# ATSAML11E15A register map
Vendor: Microchip Technology; Series: SAML11; File version: 0
CPU: CM23 r0p0, selectable endian, MPU, no FPU, 2 interrupt priority bits
Registers are 32-bit, read-write, reset 0x0 unless marked. A register's access mark holds for its fields unless they carry their own. Offsets are from the block's base; [hi:lo] are bit positions; 'fields as' and 'values as' point back to an identical list.

## OPAMP — Operational Amplifier
Base 0x42003000; register names take the prefix OPAMP_
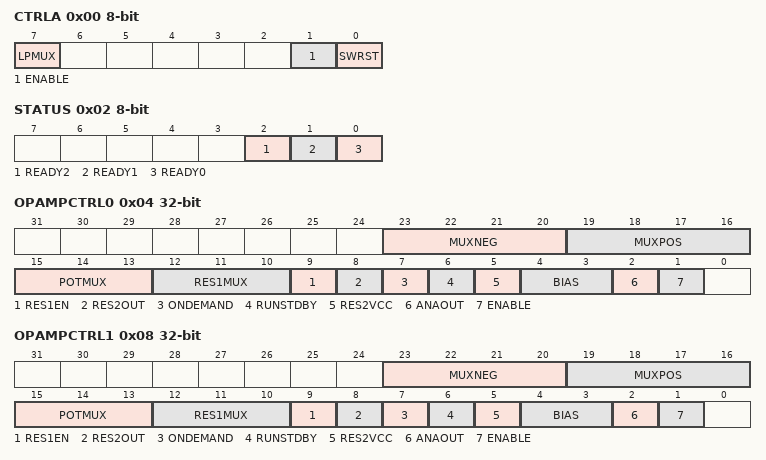
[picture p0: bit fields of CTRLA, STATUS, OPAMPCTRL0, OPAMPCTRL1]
0x00 CTRLA 8-bit — Control A
  [7] LPMUX — Low-Power Mux
  [1] ENABLE
  [0] SWRST — Software Reset
0x02 STATUS 8-bit ro
  [2] READY2 — OPAMP 2 Ready
  [1] READY1 — OPAMP 1 Ready
  [0] READY0 — OPAMP 0 Ready
0x04 OPAMPCTRL0 — OPAMP0 Control
  [23:20] MUXNEG — Negative Input Mux Selection
    0=OA0NEG (Negative I/O pin); 1=OA0TAP (Resistor ladder 0 taps); 2=REFERENCE_DAC (REFERENCE or DAC output); 3=OA0OUT (OPAMP0 output)
  [19:16] MUXPOS — Positive Input Mux Selection
    0=OA0POS (Positive I/O pin); 1=OA0TAP (Resistor ladder 0 taps); 2=REFERENCE_DAC (REFERENCE or DAC output); 3=GND (Ground)
  [15:13] POTMUX — Potentiometer Selection
    0=14R_2R (Gain = 0.14); 1=12R_4R (Gain = 0.33); 2=8R_8R (Gain = 1); 3=6R_10R (Gain = 1.67); 4=4R_12R (Gain = 3); 5=3R_13R (Gain = 4.33); 6=2R_14R (Gain = 7); 7=R_15R (Gain = 15)
  [12:10] RES1MUX — Resistor 1 Mux
    0=OAxPOS (Positive inout of OPAMPx); 1=OAxNEG (Negative input of OPAMPx); 2=DAC (DAC output); 3=GND (Ground); 4=RG_CONN
  [9] RES1EN — Resistor 1 Enable
  [8] RES2OUT — Resistor ladder To Output
  [7] ONDEMAND — On Demand Control
  [6] RUNSTDBY — Run in Standby
  [5] RES2VCC — Resistor ladder To VCC
  [4:3] BIAS — Bias Selection
  [2] ANAOUT — Analog Output
  [1] ENABLE — Operational Amplifier Enable
0x08 OPAMPCTRL1 — OPAMP1 Control
  [23:20] MUXNEG — Negative Input Mux Selection
    values as OPAMPCTRL0.MUXNEG
  [19:16] MUXPOS — Positive Input Mux Selection
    0=OA1POS (Positive I/O pin); 1=OA1TAP (Resistor ladder 1 taps); 2=REFERENCE_DAC (REFERENCE or DAC output); 3=GND (Ground); 4=OA0OUT (OPAMP0 output)
  [15:13] POTMUX — Potentiometer Selection
    values as OPAMPCTRL0.POTMUX
  [12:10] RES1MUX — Resistor 1 Mux
    0=OAxPOS (Positive inout of OPAMPx); 1=OAxNEG (Negative input of OPAMPx); 2=OA0OUT (OPAMP0 output); 3=GND (Ground); 4=RG_CONN
  [9] RES1EN — Resistor 1 Enable
  [8] RES2OUT — Resistor ladder To Output
  [7] ONDEMAND — On Demand Control
  [6] RUNSTDBY — Run in Standby
  [5] RES2VCC — Resistor ladder To VCC
  [4:3] BIAS — Bias Selection
  [2] ANAOUT — Analog Output
  [1] ENABLE — Operational Amplifier Enable
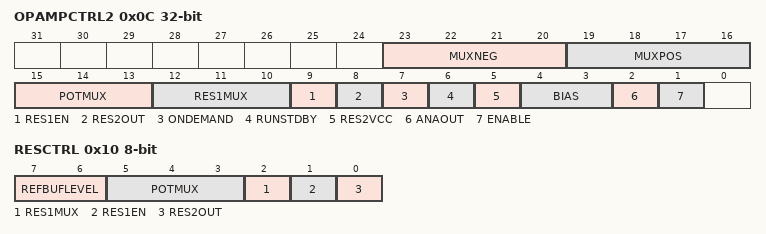
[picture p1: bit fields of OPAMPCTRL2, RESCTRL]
0x0C OPAMPCTRL2 — OPAMP2 Control
  [23:20] MUXNEG — Negative Input Mux Selection
    values as OPAMPCTRL0.MUXNEG
  [19:16] MUXPOS — Positive Input Mux Selection
    0=OA2POS (Positive I/O pin); 1=OA2TAP (Resistor ladder 2 taps); 2=REFERENCE_DAC (REFERENCE or DAC output); 3=GND (Ground); 4=OA1OUT (OPAMP1 output); 5=OA0POS (Positive I/O pin OPA0); 6=OA1POS (Positive I/O pin OPA1); 7=OA0TAP (OPAMP0 Resistor Ladder Taps); 7=RES3TAP (Resistor ladder 3 taps)
  [15:13] POTMUX — Potentiometer Selection
    values as OPAMPCTRL0.POTMUX
  [12:10] RES1MUX — Resistor 1 Mux
    0=OAxPOS (Positive inout of OPAMPx); 1=OAxNEG (Negative input of OPAMPx); 2=OA1OUT (OPAMP1 output); 3=GND (Ground)
  [9] RES1EN — Resistor 1 Enable
  [8] RES2OUT — Resistor ladder To Output
  [7] ONDEMAND — On Demand Control
  [6] RUNSTDBY — Run in Standby
  [5] RES2VCC — Resistor ladder To VCC
  [4:3] BIAS — Bias Selection
  [2] ANAOUT — Analog Output
  [1] ENABLE — Operational Amplifier Enable
0x10 RESCTRL 8-bit — Resister Control
  [7:6] REFBUFLEVEL — Reference output voltage level select
    0=1_1v; 1=1_25v; 2=1_6v
  [5:3] POTMUX — Potentiometer Selection
    values as OPAMPCTRL0.POTMUX
  [2] RES1MUX — Resistor 1 Mux
    0=DAC (DAC output); 1=REFBUF (REFERENCE output)
  [1] RES1EN — Resistor 1 Enable
  [0] RES2OUT — Resistor ladder To Output

## OSC32KCTRL — 32k Oscillators Control
Base 0x40001400; register names take the prefix OSC32KCTRL_
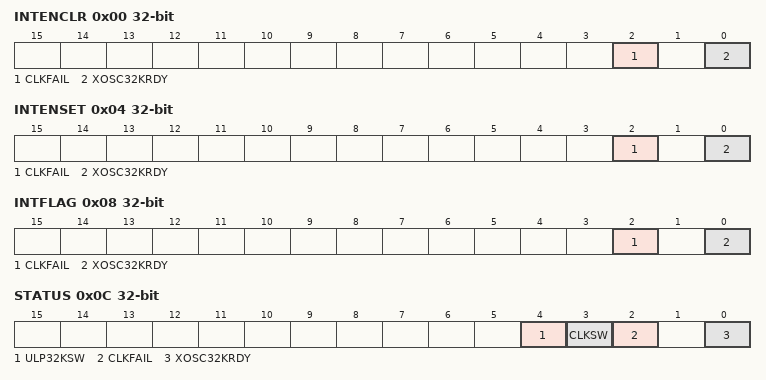
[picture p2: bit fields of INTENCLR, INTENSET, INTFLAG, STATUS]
0x00 INTENCLR — Interrupt Enable Clear
  [2] CLKFAIL — XOSC32K Clock Failure Detector Interrupt Enable
  [0] XOSC32KRDY — XOSC32K Ready Interrupt Enable
0x04 INTENSET — Interrupt Enable Set
  fields as INTENCLR
0x08 INTFLAG — Interrupt Flag Status and Clear
  [2] CLKFAIL — XOSC32K Clock Failure Detector
  [0] XOSC32KRDY — XOSC32K Ready
0x0C STATUS ro — Power and Clocks Status
  [4] ULP32KSW — OSCULP32K Clock Switch
  [3] CLKSW — XOSC32K Clock switch
  [2] CLKFAIL — XOSC32K Clock Failure Detector
  [0] XOSC32KRDY — XOSC32K Ready
0x10 RTCCTRL 8-bit — RTC Clock Selection
  [2:0] RTCSEL
    0=ULP1K (1.024kHz from 32kHz internal ULP oscillator); 1=ULP32K (32.768kHz from 32kHz internal ULP oscillator); 4=XOSC1K (1.024kHz from 32.768kHz external oscillator); 5=XOSC32K (32.768kHz from 32.768kHz external crystal oscillator)
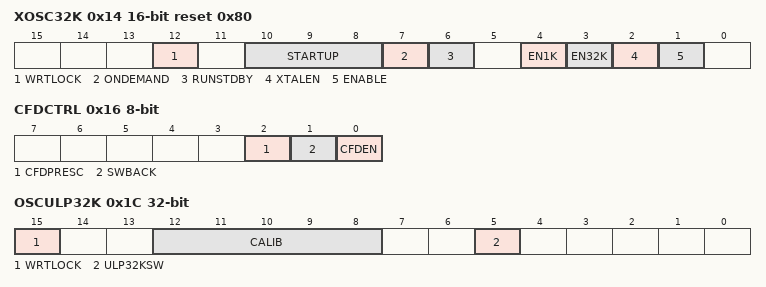
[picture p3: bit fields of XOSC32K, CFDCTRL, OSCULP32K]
0x14 XOSC32K 16-bit reset 0x80 — 32kHz External Crystal Oscillator (XOSC32K) Control
  [12] WRTLOCK — Write Lock
  [10:8] STARTUP — Oscillator Start-Up Time
    0=CYCLE1 (0.122 ms); 1=CYCLE32 (1.068 ms); 2=CYCLE2048 (62.6 ms); 3=CYCLE4096 (125 ms); 4=CYCLE16384 (500 ms); 5=CYCLE32768 (1000 ms); 6=CYCLE65536 (2000 ms); 7=CYCLE131072 (4000 ms)
  [7] ONDEMAND — On Demand Control
  [6] RUNSTDBY — Run in Standby
  [4] EN1K — 1kHz Output Enable
  [3] EN32K — 32kHz Output Enable
  [2] XTALEN — Crystal Oscillator Enable
  [1] ENABLE — Oscillator Enable
0x16 CFDCTRL 8-bit — Clock Failure Detector Control
  [2] CFDPRESC — Clock Failure Detector Prescaler
  [1] SWBACK — Clock Switch Back
  [0] CFDEN — Clock Failure Detector Enable
0x17 EVCTRL 8-bit — Event Control
  [0] CLKFAILEO — Clock Failure Detector Event Output Enable
0x1C OSCULP32K — 32kHz Ultra Low Power Internal Oscillator (OSCULP32K) Control
  [15] WRTLOCK — Write Lock
  [12:8] CALIB — Oscillator Calibration
  [5] ULP32KSW — OSCULP32K Clock Switch Enable

## Notices in the file
Copyright (c) 2017 Microchip Technology Inc.
SPDX-License-Identifier: Apache-2.0
Licensed under the Apache License, Version 2.0 (the "License");
you may not use this file except in compliance with the License.
You may obtain a copy of the License at
http://www.apache.org/licenses/LICENSE-2.0
Unless required by applicable law or agreed to in writing, software
distributed under the License is distributed on an "AS IS" BASIS,
WITHOUT WARRANTIES OR CONDITIONS OF ANY KIND, either express or implied.
See the License for the specific language governing permissions and
limitations under the License.
